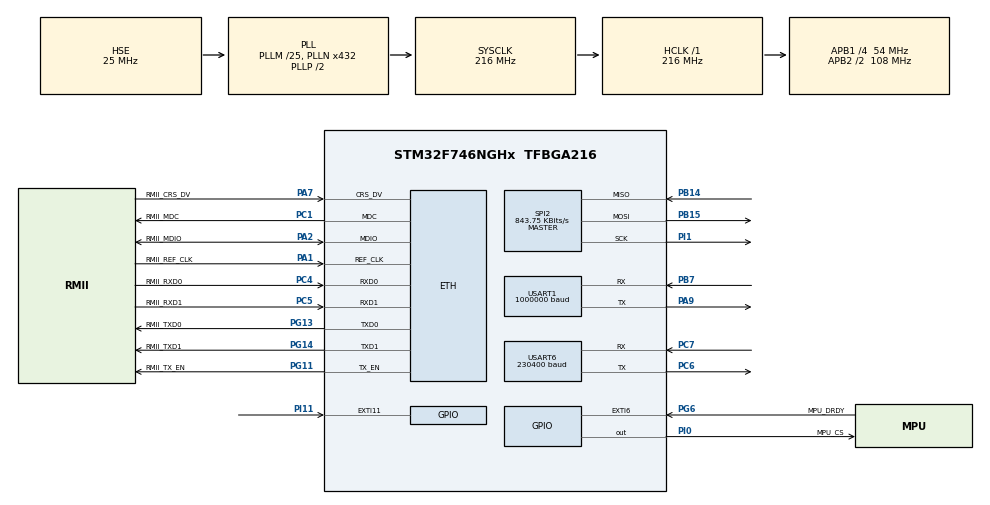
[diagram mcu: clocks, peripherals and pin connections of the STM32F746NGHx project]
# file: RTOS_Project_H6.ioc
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CORTEX_M7.default_mode_Activation=1
Dma.Request0=SPI2_RX
Dma.Request1=SPI2_TX
Dma.Request2=USART1_RX
Dma.Request3=USART1_TX
Dma.Request4=USART6_RX
Dma.Request5=USART6_TX
Dma.SPI2_RX.0.Direction=DMA_PERIPH_TO_MEMORY
Dma.SPI2_RX.0.FIFOMode=DMA_FIFOMODE_DISABLE
Dma.SPI2_RX.0.Instance=DMA1_Stream3
Dma.SPI2_RX.0.MemDataAlignment=DMA_MDATAALIGN_BYTE
Dma.SPI2_RX.0.MemInc=DMA_MINC_ENABLE
Dma.SPI2_RX.0.Mode=DMA_NORMAL
Dma.SPI2_RX.0.PeriphDataAlignment=DMA_PDATAALIGN_BYTE
Dma.SPI2_RX.0.PeriphInc=DMA_PINC_DISABLE
Dma.SPI2_RX.0.Priority=DMA_PRIORITY_HIGH
Dma.SPI2_TX.1.Direction=DMA_MEMORY_TO_PERIPH
Dma.SPI2_TX.1.FIFOMode=DMA_FIFOMODE_DISABLE
Dma.SPI2_TX.1.Instance=DMA1_Stream4
Dma.SPI2_TX.1.MemDataAlignment=DMA_MDATAALIGN_BYTE
Dma.SPI2_TX.1.MemInc=DMA_MINC_ENABLE
Dma.SPI2_TX.1.Mode=DMA_NORMAL
Dma.SPI2_TX.1.PeriphDataAlignment=DMA_PDATAALIGN_BYTE
Dma.SPI2_TX.1.PeriphInc=DMA_PINC_DISABLE
Dma.SPI2_TX.1.Priority=DMA_PRIORITY_LOW
Dma.USART1_RX.2.Direction=DMA_PERIPH_TO_MEMORY
Dma.USART1_RX.2.FIFOMode=DMA_FIFOMODE_DISABLE
Dma.USART1_RX.2.Instance=DMA2_Stream2
Dma.USART1_RX.2.MemDataAlignment=DMA_MDATAALIGN_BYTE
Dma.USART1_RX.2.MemInc=DMA_MINC_ENABLE
Dma.USART1_RX.2.Mode=DMA_CIRCULAR
Dma.USART1_RX.2.PeriphDataAlignment=DMA_PDATAALIGN_BYTE
Dma.USART1_RX.2.PeriphInc=DMA_PINC_DISABLE
Dma.USART1_RX.2.Priority=DMA_PRIORITY_MEDIUM
Dma.USART1_TX.3.Direction=DMA_MEMORY_TO_PERIPH
Dma.USART1_TX.3.FIFOMode=DMA_FIFOMODE_DISABLE
Dma.USART1_TX.3.Instance=DMA2_Stream7
Dma.USART1_TX.3.MemDataAlignment=DMA_MDATAALIGN_BYTE
Dma.USART1_TX.3.MemInc=DMA_MINC_ENABLE
Dma.USART1_TX.3.Mode=DMA_NORMAL
Dma.USART1_TX.3.PeriphDataAlignment=DMA_PDATAALIGN_BYTE
Dma.USART1_TX.3.PeriphInc=DMA_PINC_DISABLE
Dma.USART1_TX.3.Priority=DMA_PRIORITY_LOW
Dma.USART6_RX.4.Direction=DMA_PERIPH_TO_MEMORY
Dma.USART6_RX.4.FIFOMode=DMA_FIFOMODE_DISABLE
Dma.USART6_RX.4.Instance=DMA2_Stream1
Dma.USART6_RX.4.MemDataAlignment=DMA_MDATAALIGN_BYTE
Dma.USART6_RX.4.MemInc=DMA_MINC_ENABLE
Dma.USART6_RX.4.Mode=DMA_CIRCULAR
Dma.USART6_RX.4.PeriphDataAlignment=DMA_PDATAALIGN_BYTE
Dma.USART6_RX.4.PeriphInc=DMA_PINC_DISABLE
Dma.USART6_RX.4.Priority=DMA_PRIORITY_LOW
Dma.USART6_TX.5.Direction=DMA_MEMORY_TO_PERIPH
Dma.USART6_TX.5.FIFOMode=DMA_FIFOMODE_DISABLE
Dma.USART6_TX.5.Instance=DMA2_Stream6
Dma.USART6_TX.5.MemDataAlignment=DMA_MDATAALIGN_BYTE
Dma.USART6_TX.5.MemInc=DMA_MINC_ENABLE
Dma.USART6_TX.5.Mode=DMA_NORMAL
Dma.USART6_TX.5.PeriphDataAlignment=DMA_PDATAALIGN_BYTE
Dma.USART6_TX.5.PeriphInc=DMA_PINC_DISABLE
Dma.USART6_TX.5.Priority=DMA_PRIORITY_LOW
ETH.MediaInterface=HAL_ETH_RMII_MODE
ETH.PHY_Name=LAN8742A_PHY_ADDRESS
ETH.PHY_RESET_DELAY=0x00000FFF
ETH.PhyAddress=0
ETH.RxBuffLen=1536
Mcu.Family=STM32F7
Mcu.Name=STM32F746NGHx
Mcu.Package=TFBGA216
NVIC.DMA1_Stream3_IRQn=true\:5\:0\:false\:false\:true\:false\:true\:true
NVIC.DMA1_Stream4_IRQn=true\:5\:0\:false\:false\:true\:false\:true\:true
NVIC.DMA2_Stream1_IRQn=true\:8\:0\:false\:false\:true\:false\:true\:true
NVIC.DMA2_Stream2_IRQn=true\:5\:0\:false\:false\:true\:false\:true\:true
NVIC.DMA2_Stream6_IRQn=true\:8\:0\:false\:false\:true\:false\:true\:true
NVIC.DMA2_Stream7_IRQn=true\:5\:0\:false\:false\:true\:false\:true\:true
NVIC.EXTI9_5_IRQn=true\:6\:0\:false\:false\:true\:false\:true\:true
NVIC.PriorityGroup=NVIC_PRIORITYGROUP_4
NVIC.TIM1_UP_TIM10_IRQn=true\:15\:0\:false\:false\:true\:false\:true\:true
NVIC.TimeBase=TIM1_UP_TIM10_IRQn
NVIC.TimeBaseIP=TIM1
NVIC.USART1_IRQn=true\:5\:0\:false\:false\:true\:false\:true\:true
NVIC.USART6_IRQn=true\:8\:0\:false\:false\:true\:false\:true\:true
PA1.GPIO_Label=RMII_REF_CLK
PA1.Mode=RMII
PA1.Signal=ETH_REF_CLK
PA13.Mode=Serial_Wire
PA13.Signal=SYS_JTMS-SWDIO
PA14.Mode=Serial_Wire
PA14.Signal=SYS_JTCK-SWCLK
PA2.GPIO_Label=RMII_MDIO
PA2.Mode=RMII
PA2.Signal=ETH_MDIO
PA7.GPIO_Label=RMII_CRS_DV
PA7.Mode=RMII
PA7.Signal=ETH_CRS_DV
PA9.Mode=Asynchronous
PA9.Signal=USART1_TX
PB14.Mode=Full_Duplex_Master
PB14.Signal=SPI2_MISO
PB15.Mode=Full_Duplex_Master
PB15.Signal=SPI2_MOSI
PB7.Mode=Asynchronous
PB7.Signal=USART1_RX
PC1.GPIO_Label=RMII_MDC
PC1.Mode=RMII
PC1.Signal=ETH_MDC
PC14/OSC32_IN.Mode=LSE-External-Oscillator
PC14/OSC32_IN.Signal=RCC_OSC32_IN
PC15/OSC32_OUT.Mode=LSE-External-Oscillator
PC15/OSC32_OUT.Signal=RCC_OSC32_OUT
PC4.GPIO_Label=RMII_RXD0
PC4.Mode=RMII
PC4.Signal=ETH_RXD0
PC5.GPIO_Label=RMII_RXD1
PC5.Mode=RMII
PC5.Signal=ETH_RXD1
PC6.Mode=Asynchronous
PC6.Signal=USART6_TX
PC7.Mode=Asynchronous
PC7.Signal=USART6_RX
PG11.GPIO_Label=RMII_TX_EN
PG11.Mode=RMII
PG11.Signal=ETH_TX_EN
PG13.GPIO_Label=RMII_TXD0
PG13.Mode=RMII
PG13.Signal=ETH_TXD0
PG14.GPIO_Label=RMII_TXD1
PG14.Mode=RMII
PG14.Signal=ETH_TXD1
PG6.GPIO_Label=MPU_DRDY
PG6.GPIO_PuPd=GPIO_PULLDOWN
PG6.Signal=GPXTI6
PH0/OSC_IN.Mode=HSE-External-Oscillator
PH0/OSC_IN.Signal=RCC_OSC_IN
PH1/OSC_OUT.Mode=HSE-External-Oscillator
PH1/OSC_OUT.Signal=RCC_OSC_OUT
PI0.GPIO_Label=MPU_CS
PI0.PinState=GPIO_PIN_SET
PI0.Signal=GPIO_Output
PI1.Mode=Full_Duplex_Master
PI1.Signal=SPI2_SCK
PI11.Signal=GPXTI11
ProjectManager.HeapSize=0x200
ProjectManager.StackSize=0x400
ProjectManager.TargetToolchain=STM32CubeIDE
RCC.AHBFreq_Value=216000000
RCC.APB1CLKDivider=RCC_HCLK_DIV4
RCC.APB1Freq_Value=54000000
RCC.APB1TimFreq_Value=108000000
RCC.APB2CLKDivider=RCC_HCLK_DIV2
RCC.APB2Freq_Value=108000000
RCC.APB2TimFreq_Value=216000000
RCC.CortexFreq_Value=216000000
RCC.HCLKFreq_Value=216000000
RCC.HSE_VALUE=25000000
RCC.HSI_VALUE=16000000
RCC.PLLM=25
RCC.PLLN=432
RCC.PLLQ=9
RCC.PLLSourceVirtual=RCC_PLLSOURCE_HSE
RCC.SYSCLKFreq_VALUE=216000000
RCC.SYSCLKSource=RCC_SYSCLKSOURCE_PLLCLK
RCC.USBFreq_Value=48000000
RCC.VCOOutputFreq_Value=432000000
SPI2.BaudRatePrescaler=SPI_BAUDRATEPRESCALER_64
SPI2.CLKPhase=SPI_PHASE_2EDGE
SPI2.CLKPolarity=SPI_POLARITY_HIGH
SPI2.CalculateBaudRate=843.75 KBits/s
SPI2.DataSize=SPI_DATASIZE_8BIT
SPI2.Direction=SPI_DIRECTION_2LINES
SPI2.Mode=SPI_MODE_MASTER
SPI2.VirtualType=VM_MASTER
USART1.BaudRate=1000000
USART1.VirtualMode-Asynchronous=VM_ASYNC
USART6.BaudRate=230400
USART6.VirtualMode-Asynchronous=VM_ASYNC
VP_SYS_VS_tim1.Mode=TIM1
board=STM32F746G-DISCO

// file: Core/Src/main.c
/* USER CODE BEGIN Header */
/**
  ******************************************************************************
  * @file           : main.c
  * @brief          : Main program body
  ******************************************************************************
  * @attention
  *
  * Copyright (c) 2026 STMicroelectronics.
  * All rights reserved.
  *
  * This software is licensed under terms that can be found in the LICENSE file
  * in the root directory of this software component.
  * If no LICENSE file comes with this software, it is provided AS-IS.
  *
  ******************************************************************************
  */
/* USER CODE END Header */
#include "main.h"
#include "string.h"

/* USER CODE BEGIN Includes */
#include "FreeRTOS.h"
#include "task.h"
#include "app_main.h"
/* USER CODE END Includes */

#if defined ( __ICCARM__ ) /*!< IAR Compiler */
#pragma location=0x2004c000
ETH_DMADescTypeDef  DMARxDscrTab[ETH_RX_DESC_CNT]; /* Ethernet Rx DMA Descriptors */
#pragma location=0x2004c0a0
ETH_DMADescTypeDef  DMATxDscrTab[ETH_TX_DESC_CNT]; /* Ethernet Tx DMA Descriptors */

#elif defined ( __CC_ARM )  /* MDK ARM Compiler */

__attribute__((at(0x2004c000))) ETH_DMADescTypeDef  DMARxDscrTab[ETH_RX_DESC_CNT]; /* Ethernet Rx DMA Descriptors */
__attribute__((at(0x2004c0a0))) ETH_DMADescTypeDef  DMATxDscrTab[ETH_TX_DESC_CNT]; /* Ethernet Tx DMA Descriptors */

#elif defined ( __GNUC__ ) /* GNU Compiler */

ETH_DMADescTypeDef DMARxDscrTab[ETH_RX_DESC_CNT] __attribute__((section(".RxDecripSection"))); /* Ethernet Rx DMA Descriptors */
ETH_DMADescTypeDef DMATxDscrTab[ETH_TX_DESC_CNT] __attribute__((section(".TxDecripSection")));   /* Ethernet Tx DMA Descriptors */
#endif

ETH_TxPacketConfig TxConfig;

ETH_HandleTypeDef heth;

SPI_HandleTypeDef hspi2;
DMA_HandleTypeDef hdma_spi2_rx;
DMA_HandleTypeDef hdma_spi2_tx;

UART_HandleTypeDef huart1;
UART_HandleTypeDef huart6;
DMA_HandleTypeDef hdma_usart1_rx;
DMA_HandleTypeDef hdma_usart1_tx;
DMA_HandleTypeDef hdma_usart6_rx;
DMA_HandleTypeDef hdma_usart6_tx;

void SystemClock_Config(void);
static void MPU_Config(void);
static void MX_GPIO_Init(void);
static void MX_DMA_Init(void);
static void MX_SPI2_Init(void);
static void MX_USART1_UART_Init(void);
static void MX_USART6_UART_Init(void);

int main(void)
{

  /* USER CODE BEGIN 1 */
  /* Instruction cache: at 216 MHz the flash needs 7 wait states; code runs
   * from the AXI flash path, where only the L1 I-cache hides them. The
   * D-cache stays off: the DMA buffers (UART, SPI) rely on it (no cache
   * maintenance in App/). */
  SCB_EnableICache();
  /* USER CODE END 1 */

  /* MPU Configuration--------------------------------------------------------*/
  MPU_Config();

  /* MCU Configuration--------------------------------------------------------*/

  /* Reset of all peripherals, Initializes the Flash interface and the Systick. */
  HAL_Init();

  /* Configure the system clock */
  SystemClock_Config();

  /* Initialize all configured peripherals */
  MX_GPIO_Init();
  MX_DMA_Init();
  MX_SPI2_Init();
  MX_USART1_UART_Init();
  MX_USART6_UART_Init();
  /* USER CODE BEGIN 2 */
  /* Every application RTOS object and the IP task (app_main.c, step 18).
   * MX_ETH_Init() is generated but intentionally not called: the network
   * runs on VNET (net_app.c). A failed step does not return (App_Halt). */
  App_Init();

  /* Start the kernel (1 ms tick). */
  vTaskStartScheduler();
  /* USER CODE END 2 */

  /* Infinite loop */
  while (1)
  {

  }
}

void SystemClock_Config(void)
{
  RCC_OscInitTypeDef RCC_OscInitStruct = {0};
  RCC_ClkInitTypeDef RCC_ClkInitStruct = {0};

  /** Configure LSE Drive Capability
  */
  HAL_PWR_EnableBkUpAccess();

  /** Configure the main internal regulator output voltage
  */
  __HAL_RCC_PWR_CLK_ENABLE();
  __HAL_PWR_VOLTAGESCALING_CONFIG(PWR_REGULATOR_VOLTAGE_SCALE1);

  /** Initializes the RCC Oscillators according to the specified parameters
  * in the RCC_OscInitTypeDef structure.
  */
  RCC_OscInitStruct.OscillatorType = RCC_OSCILLATORTYPE_HSE;
  RCC_OscInitStruct.HSEState = RCC_HSE_ON;
  RCC_OscInitStruct.PLL.PLLState = RCC_PLL_ON;
  RCC_OscInitStruct.PLL.PLLSource = RCC_PLLSOURCE_HSE;
  RCC_OscInitStruct.PLL.PLLM = 25;
  RCC_OscInitStruct.PLL.PLLN = 432;
  RCC_OscInitStruct.PLL.PLLP = RCC_PLLP_DIV2;
  RCC_OscInitStruct.PLL.PLLQ = 9;
  if (HAL_RCC_OscConfig(&RCC_OscInitStruct) != HAL_OK)
  {
    Error_Handler();
  }

  /** Activate the Over-Drive mode
  */
  if (HAL_PWREx_EnableOverDrive() != HAL_OK)
  {
    Error_Handler();
  }

  /** Initializes the CPU, AHB and APB buses clocks
  */
  RCC_ClkInitStruct.ClockType = RCC_CLOCKTYPE_HCLK|RCC_CLOCKTYPE_SYSCLK
                              |RCC_CLOCKTYPE_PCLK1|RCC_CLOCKTYPE_PCLK2;
  RCC_ClkInitStruct.SYSCLKSource = RCC_SYSCLKSOURCE_PLLCLK;
  RCC_ClkInitStruct.AHBCLKDivider = RCC_SYSCLK_DIV1;
  RCC_ClkInitStruct.APB1CLKDivider = RCC_HCLK_DIV4;
  RCC_ClkInitStruct.APB2CLKDivider = RCC_HCLK_DIV2;

  if (HAL_RCC_ClockConfig(&RCC_ClkInitStruct, FLASH_LATENCY_7) != HAL_OK)
  {
    Error_Handler();
  }
}

void MX_ETH_Init(void)
{

   static uint8_t MACAddr[6];

  heth.Instance = ETH;
  MACAddr[0] = 0x00;
  MACAddr[1] = 0x80;
  MACAddr[2] = 0xE1;
  MACAddr[3] = 0x00;
  MACAddr[4] = 0x00;
  MACAddr[5] = 0x00;
  heth.Init.MACAddr = &MACAddr[0];
  heth.Init.MediaInterface = HAL_ETH_RMII_MODE;
  heth.Init.TxDesc = DMATxDscrTab;
  heth.Init.RxDesc = DMARxDscrTab;
  heth.Init.RxBuffLen = 1536;

  if (HAL_ETH_Init(&heth) != HAL_OK)
  {
    Error_Handler();
  }

  memset(&TxConfig, 0 , sizeof(ETH_TxPacketConfig));
  TxConfig.Attributes = ETH_TX_PACKETS_FEATURES_CSUM | ETH_TX_PACKETS_FEATURES_CRCPAD;
  TxConfig.ChecksumCtrl = ETH_CHECKSUM_IPHDR_PAYLOAD_INSERT_PHDR_CALC;
  TxConfig.CRCPadCtrl = ETH_CRC_PAD_INSERT;

}

static void MX_SPI2_Init(void)
{

  /* SPI2 parameter configuration*/
  hspi2.Instance = SPI2;
  hspi2.Init.Mode = SPI_MODE_MASTER;
  hspi2.Init.Direction = SPI_DIRECTION_2LINES;
  hspi2.Init.DataSize = SPI_DATASIZE_8BIT;
  hspi2.Init.CLKPolarity = SPI_POLARITY_HIGH;
  hspi2.Init.CLKPhase = SPI_PHASE_2EDGE;
  hspi2.Init.NSS = SPI_NSS_SOFT;
  hspi2.Init.BaudRatePrescaler = SPI_BAUDRATEPRESCALER_64;
  hspi2.Init.FirstBit = SPI_FIRSTBIT_MSB;
  hspi2.Init.TIMode = SPI_TIMODE_DISABLE;
  hspi2.Init.CRCCalculation = SPI_CRCCALCULATION_DISABLE;
  hspi2.Init.CRCPolynomial = 7;
  hspi2.Init.CRCLength = SPI_CRC_LENGTH_DATASIZE;
  hspi2.Init.NSSPMode = SPI_NSS_PULSE_DISABLE;
  if (HAL_SPI_Init(&hspi2) != HAL_OK)
  {
    Error_Handler();
  }

}

static void MX_USART1_UART_Init(void)
{

  huart1.Instance = USART1;
  huart1.Init.BaudRate = 1000000;
  huart1.Init.WordLength = UART_WORDLENGTH_8B;
  huart1.Init.StopBits = UART_STOPBITS_1;
  huart1.Init.Parity = UART_PARITY_NONE;
  huart1.Init.Mode = UART_MODE_TX_RX;
  huart1.Init.HwFlowCtl = UART_HWCONTROL_NONE;
  huart1.Init.OverSampling = UART_OVERSAMPLING_16;
  huart1.Init.OneBitSampling = UART_ONE_BIT_SAMPLE_DISABLE;
  huart1.AdvancedInit.AdvFeatureInit = UART_ADVFEATURE_NO_INIT;
  if (HAL_UART_Init(&huart1) != HAL_OK)
  {
    Error_Handler();
  }

}

static void MX_USART6_UART_Init(void)
{

  huart6.Instance = USART6;
  huart6.Init.BaudRate = 230400;
  huart6.Init.WordLength = UART_WORDLENGTH_8B;
  huart6.Init.StopBits = UART_STOPBITS_1;
  huart6.Init.Parity = UART_PARITY_NONE;
  huart6.Init.Mode = UART_MODE_TX_RX;
  huart6.Init.HwFlowCtl = UART_HWCONTROL_NONE;
  huart6.Init.OverSampling = UART_OVERSAMPLING_16;
  huart6.Init.OneBitSampling = UART_ONE_BIT_SAMPLE_DISABLE;
  huart6.AdvancedInit.AdvFeatureInit = UART_ADVFEATURE_NO_INIT;
  if (HAL_UART_Init(&huart6) != HAL_OK)
  {
    Error_Handler();
  }

}

static void MX_DMA_Init(void)
{

  /* DMA controller clock enable */
  __HAL_RCC_DMA1_CLK_ENABLE();
  __HAL_RCC_DMA2_CLK_ENABLE();

  /* DMA interrupt init */
  /* DMA1_Stream3_IRQn interrupt configuration */
  HAL_NVIC_SetPriority(DMA1_Stream3_IRQn, 5, 0);
  HAL_NVIC_EnableIRQ(DMA1_Stream3_IRQn);
  /* DMA1_Stream4_IRQn interrupt configuration */
  HAL_NVIC_SetPriority(DMA1_Stream4_IRQn, 5, 0);
  HAL_NVIC_EnableIRQ(DMA1_Stream4_IRQn);
  /* DMA2_Stream1_IRQn interrupt configuration */
  HAL_NVIC_SetPriority(DMA2_Stream1_IRQn, 8, 0);
  HAL_NVIC_EnableIRQ(DMA2_Stream1_IRQn);
  /* DMA2_Stream2_IRQn interrupt configuration */
  HAL_NVIC_SetPriority(DMA2_Stream2_IRQn, 5, 0);
  HAL_NVIC_EnableIRQ(DMA2_Stream2_IRQn);
  /* DMA2_Stream6_IRQn interrupt configuration */
  HAL_NVIC_SetPriority(DMA2_Stream6_IRQn, 8, 0);
  HAL_NVIC_EnableIRQ(DMA2_Stream6_IRQn);
  /* DMA2_Stream7_IRQn interrupt configuration */
  HAL_NVIC_SetPriority(DMA2_Stream7_IRQn, 5, 0);
  HAL_NVIC_EnableIRQ(DMA2_Stream7_IRQn);

}

static void MX_GPIO_Init(void)
{
  GPIO_InitTypeDef GPIO_InitStruct = {0};

  /* GPIO Ports Clock Enable */
  __HAL_RCC_GPIOG_CLK_ENABLE();
  __HAL_RCC_GPIOA_CLK_ENABLE();
  __HAL_RCC_GPIOB_CLK_ENABLE();
  __HAL_RCC_GPIOI_CLK_ENABLE();
  __HAL_RCC_GPIOC_CLK_ENABLE();
  __HAL_RCC_GPIOH_CLK_ENABLE();

  /*Configure GPIO pin Output Level */
  HAL_GPIO_WritePin(MPU_CS_GPIO_Port, MPU_CS_Pin, GPIO_PIN_SET);

  /*Configure GPIO pin : MPU_CS_Pin */
  GPIO_InitStruct.Pin = MPU_CS_Pin;
  GPIO_InitStruct.Mode = GPIO_MODE_OUTPUT_PP;
  GPIO_InitStruct.Pull = GPIO_NOPULL;
  GPIO_InitStruct.Speed = GPIO_SPEED_FREQ_LOW;
  HAL_GPIO_Init(MPU_CS_GPIO_Port, &GPIO_InitStruct);

  /*Configure GPIO pin : PI11 */
  GPIO_InitStruct.Pin = GPIO_PIN_11;
  GPIO_InitStruct.Mode = GPIO_MODE_IT_RISING;
  GPIO_InitStruct.Pull = GPIO_NOPULL;
  HAL_GPIO_Init(GPIOI, &GPIO_InitStruct);

  /*Configure GPIO pin : MPU_DRDY_Pin */
  GPIO_InitStruct.Pin = MPU_DRDY_Pin;
  GPIO_InitStruct.Mode = GPIO_MODE_IT_RISING;
  GPIO_InitStruct.Pull = GPIO_PULLDOWN;
  HAL_GPIO_Init(MPU_DRDY_GPIO_Port, &GPIO_InitStruct);

  /* EXTI interrupt init*/
  HAL_NVIC_SetPriority(EXTI9_5_IRQn, 6, 0);
  HAL_NVIC_EnableIRQ(EXTI9_5_IRQn);

}

 /* MPU Configuration */

void MPU_Config(void)
{
  MPU_Region_InitTypeDef MPU_InitStruct = {0};

  /* Disables the MPU */
  HAL_MPU_Disable();

  /** Initializes and configures the Region and the memory to be protected
  */
  MPU_InitStruct.Enable = MPU_REGION_ENABLE;
  MPU_InitStruct.Number = MPU_REGION_NUMBER0;
  MPU_InitStruct.BaseAddress = 0x0;
  MPU_InitStruct.Size = MPU_REGION_SIZE_4GB;
  MPU_InitStruct.SubRegionDisable = 0x87;
  MPU_InitStruct.TypeExtField = MPU_TEX_LEVEL0;
  MPU_InitStruct.AccessPermission = MPU_REGION_NO_ACCESS;
  MPU_InitStruct.DisableExec = MPU_INSTRUCTION_ACCESS_DISABLE;
  MPU_InitStruct.IsShareable = MPU_ACCESS_SHAREABLE;
  MPU_InitStruct.IsCacheable = MPU_ACCESS_NOT_CACHEABLE;
  MPU_InitStruct.IsBufferable = MPU_ACCESS_NOT_BUFFERABLE;

  HAL_MPU_ConfigRegion(&MPU_InitStruct);
  /* Enables the MPU */
  HAL_MPU_Enable(MPU_PRIVILEGED_DEFAULT);

}

void HAL_TIM_PeriodElapsedCallback(TIM_HandleTypeDef *htim)
{
  if (htim->Instance == TIM1)
  {
    HAL_IncTick();
  }
}

void Error_Handler(void)
{
  /* USER CODE BEGIN Error_Handler_Debug */
  /* One halt line on UART1, then stop (report 082 A5). Before
   * MX_USART1_UART_Init the UART is not ready: HAL_UART_Transmit returns
   * HAL_BUSY at once, no line, the stop is the same. */
  App_Halt("hal", NULL);
  /* USER CODE END Error_Handler_Debug */
}
